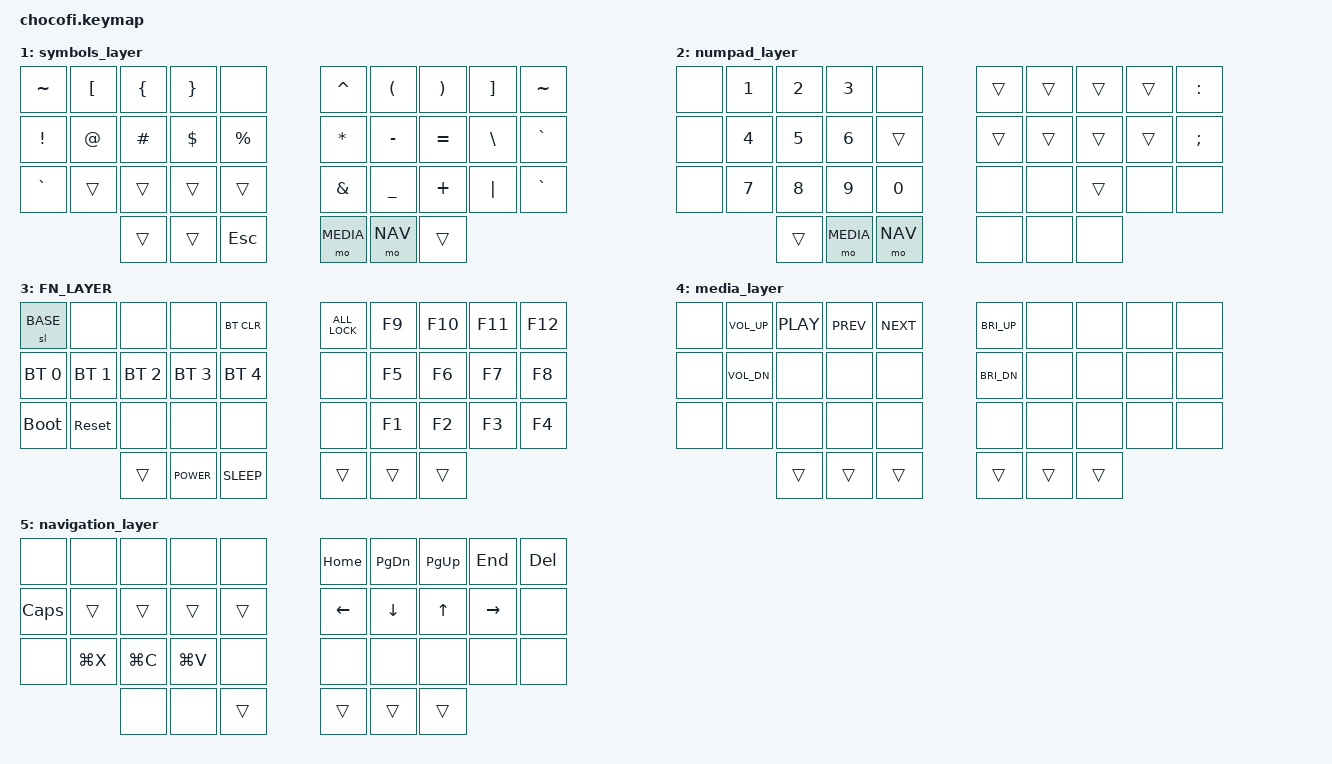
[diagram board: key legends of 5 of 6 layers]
// Copyright (c) 2022 The ZMK Contributors
// SPDX-License-Identifier: MIT

#include <behaviors.dtsi>
#include <dt-bindings/zmk/keys.h>
#include <dt-bindings/zmk/bt.h>



#define _SPC_    &kp SPACE
#define _CUT_    &kp LG(X)
#define _COPY_   &kp LG(C)
#define _PASTE_  &kp LG(V)
#define ___      &trans
#define _x_      &none

#define BASE 0
#define NUM 1
#define SYM 2
#define FN 3
#define MEDIA 4
#define NAV 5

// Home row mods macro
#define HRML(k1,k2,k3,k4) &ht LSHFT k1  &ht LALT k2  &ht LCTRL k3  &ht LGUI k4
#define HRMR(k1,k2,k3,k4) &ht RGUI k1  &ht RCTRL k2  &ht RALT k3  &ht RSHFT k4

/ {
    behaviors {
        ht: hold_tap {
            label = "hold_tap";
            compatible = "zmk,behavior-hold-tap";
            #binding-cells = <2>;
            flavor = "tap-preferred";
            tapping-term-ms = <220>;
            quick-tap-ms = <150>;
            global-quick-tap;
            bindings = <&kp>, <&kp>;
        };
    };

    keymap {
        compatible = "zmk,keymap";
        default_layer {
            bindings = <
        //╭──────────┬──────────┬──────────┬──────────┬──────────╮   ╭──────────┬──────────┬──────────┬──────────┬──────────╮
        //│  (FN) Q  │  W       │  E       │  R       │  T       │   │  Y       │  U       │  I       │  O       │  P       │
            &lt FN Q   &kp W      &kp E      &kp R      &kp T          &kp Y      &kp U      &kp I      &kp O      &kp P
        //├──────────┼──────────┼──────────┼──────────┼──────────┤   ├──────────┼──────────┼──────────┼──────────┼──────────┤
        //│  A       │  S       │  D       │  F       │  G       │   │  H       │  J       │  K       │  L       │ ' "      │
            HRML(A,        S,         D,         F)     &kp G          &kp H      HRMR(J,        K,         L,        SQT)
        //├──────────┼──────────┼──────────┼──────────┼──────────┤   ├──────────┼──────────┼──────────┼──────────┼──────────┤
        //│  Z       │  X       │  C       │  V       │  B       │   │  N       │  M       │ , <      │ . >      │ / ?      │
            &kp Z      &kp X      &kp C      &kp V      &kp B          &kp N      &kp M      &kp COMMA  &kp DOT    &kp FSLH
        //╰──────────┴──────────┴──────────┼──────────┼──────────┤   ├──────────┼──────────┼──────────┴──────────┴──────────╯
                                &kp CAPSLOCK &lt SYM TAB  _SPC_       &kp ENTER  &lt NUM BSPC  &kp ESC
        //                      ╰──────────┴──────────┴──────────╯   ╰──────────┴──────────┴──────────╯
            >;
        };

        // layer 1
        symbols_layer {
            bindings = <
        //╭──────────┬──────────┬──────────┬──────────┬──────────╮   ╭──────────┬──────────┬──────────┬──────────┬──────────╮
        //│ ~        │  [       │  {       │  }       │          │   │  ^       │  (       │  )       │  ]       │  ~       │
            &kp TILDE  &kp LBKT   &kp LBRC   &kp RBRC     _x_         &kp CARET  &kp LPAR   &kp RPAR   &kp RBKT   &kp TILDE
        //├──────────┼──────────┼──────────┼──────────┼──────────┤   ├──────────┼──────────┼──────────┼──────────┼──────────┤
        //│  !       │  @       │  #       │  $       │  %       │   │  *       │  -       │  =       │  \       │  `       │
            &kp EXCL   &kp AT     &kp HASH   &kp DLLR   &kp PRCNT      &kp ASTRK  &kp MINUS  &kp EQUAL  &kp BSLH   &kp GRAVE
        //├──────────┼──────────┼──────────┼──────────┼──────────┤   ├──────────┼──────────┼──────────┼──────────┼──────────┤
        //│ `        │          │          │          │          │   │  &       │  _       │  +       │  │       │  `       │
            &kp GRAVE    ___        ___        ___         ___         &kp AMPS   &kp UNDER  &kp PLUS   &kp PIPE   &kp GRAVE
        //╰──────────┴──────────┴──────────┼──────────┼──────────┤   ├──────────┼──────────┼──────────┴──────────┴──────────╯
                                    ___        ___       &kp ESC       &mo MEDIA  &mo NAV      ___
        //                      ╰──────────┴──────────┴──────────╯   ╰──────────┴──────────┴──────────╯
            >;
        };

        // layer 2
        numpad_layer {
            bindings = <
        //╭──────────┬──────────┬──────────┬──────────┬──────────╮   ╭──────────┬──────────┬──────────┬──────────┬──────────╮
        //│          │  1       │  2       │  3       │          │   │          │          │          │          │  :       │
              _x_       &kp N1     &kp N2     &kp N3      _x_          ___          ___        ___        ___      &kp COLON
        //├──────────┼──────────┼──────────┼──────────┼──────────┤   ├──────────┼──────────┼──────────┼──────────┼──────────┤
        //│          │  4       │  5       │  6       │          │   │          │          │          │          │  ;       │
              _x_       &kp N4     &kp N5     &kp N6      ___          ___          ___        ___        ___      &kp SEMI
        //├──────────┼──────────┼──────────┼──────────┼──────────┤   ├──────────┼──────────┼──────────┼──────────┼──────────┤
        //│          │  7       │  8       │  9       │  0       │   │          │          │          │          │          │
              _x_      &kp N7     &kp N8     &kp N9     &kp N0          _x_         _x_         ___        _x_        _x_
        //╰──────────┴──────────┴──────────┼──────────┼──────────┤   ├──────────┼──────────┼──────────┴──────────┴──────────╯
                                    ___      &mo MEDIA  &mo NAV          _x_        _x_         _x_
        //                      ╰──────────┴──────────┴──────────╯   ╰──────────┴──────────┴──────────╯
            >;
        };


        FN_LAYER {
            bindings = <
        //╭──────────┬──────────┬──────────┬──────────┬──────────╮   ╭──────────┬──────────┬──────────┬──────────┬──────────╮
        //│    -     │    -     │    -     │    -     │    -     │   │    -     │    -     │    -     │     -    │     -    │
        //├──────────┼──────────┼──────────┼──────────┼──────────┤   ├──────────┼──────────┼──────────┼──────────┼──────────┤
            &sl BASE     _x_        _x_         _x_    &bt BT_CLR   &kp C_ALL_LOCK  &kp F9    &kp F10    &kp F11    &kp F12
        //│    -     │    -     │    -     │    -     │    -     │   │    -     │    -     │    -     │     -    │     -    │
 &bt BT_SEL 0 &bt BT_SEL 1  &bt BT_SEL 2 &bt BT_SEL 3 &bt BT_SEL 4       _x_        &kp F5    &kp F6     &kp F7     &kp F8
        //│    -     │    -     │    -     │    -     │    -     │   │    -     │    -     │    -     │     -    │     -    │
          &bootloader &sys_reset    _x_        _x_         _x_            _x_       &kp F1     &kp F2     &kp F3     &kp F4
        //╰──────────┴──────────┴──────────┼──────────┼──────────┤   ├──────────┼──────────┼──────────┴──────────┴──────────╯
                                    ___   &kp C_POWER &kp C_SLEEP        ___        ___        ___
        //                      ╰──────────┴──────────┴──────────╯   ╰──────────┴──────────┴──────────╯

            >;
        };

        media_layer {
            bindings = <
        //╭──────────┬──────────┬──────────┬──────────┬──────────╮   ╭──────────┬──────────┬──────────┬──────────┬──────────╮
        //│    -     │ VOL_UP   │ PLAY     │ PREV     │ PREV     │   │          │          │          │          │          │
              _x_    &kp C_VOL_UP &kp C_PLAY &kp C_PREV &kp C_NEXT   &kp C_BRI_UP   _x_        _x_        _x_        _x_
        //├──────────┼──────────┼──────────┼──────────┼──────────┤   ├──────────┼──────────┼──────────┼──────────┼──────────┤
        //│    -     │ VOL_DOWN │          │          │          │   │          │          │          │          │          │
            _x_   &kp C_VOL_DN      _x_        _x_       _x_          &kp C_BRI_DN   _x_        _x_        _x_        _x_
        //├──────────┼──────────┼──────────┼──────────┼──────────┤   ├──────────┼──────────┼──────────┼──────────┼──────────┤
        //│          │          │          │          │          │   │          │          │          │          │          │
              _x_        _x_        _x_         _x_       _x_            _x_        _x_        _x_        _x_        _x_
        //╰──────────┴──────────┴──────────┼──────────┼──────────┤   ├──────────┼──────────┼──────────┴──────────┴──────────╯
                                    ___       ___        ___             ___        ___        ___
        //                      ╰──────────┴──────────┴──────────╯   ╰──────────┴──────────┴──────────╯
            >;
        };

        navigation_layer {
            bindings = <
        // ╭───────────────────────────────────────────────────────────╮   ╭───────────────────────────────────────────────────────────╮
        // │     _     │     _     │     _     │     _     │     _     │   │     _     │     _     │     _     │     _     │     _     │
                _x_         _x_         _x_         _x_         _x_           &kp HOME   &kp PG_DN  &kp PG_UP   &kp END         &kp DEL
        // ├───────────┼───────────┼───────────┼───────────┼───────────┤   ├───────────┼───────────┼───────────┼───────────┼───────────┤
              &kp CAPS      ___         ___         ___         ___           &kp LEFT    &kp DOWN     &kp UP    &kp RIGHT      _x_
        // ├───────────┼───────────┼───────────┼───────────┼───────────┤   ├───────────┼───────────┼───────────┼───────────┼───────────┤
        // │     _     │     _     │     _     │     _     │     _     │   │     _     │     _     │     _     │     _     │     _     │
                _x_         _CUT_      _COPY_     _PASTE_       _x_             _x_         _x_         _x_         _x_         _x_
        // ╰───────────┼───────────┼───────────┼───────────┼───────────╯   ╰───────────┼───────────┼───────────┼───────────┼───────────╯
                                        _x_         _x_         ___             ___         ___         ___
        /                          ╰────────────┴──────────┴───────────╯   ╰──────────┴──────────┴──────────╯
            >;
        };
    };
};
